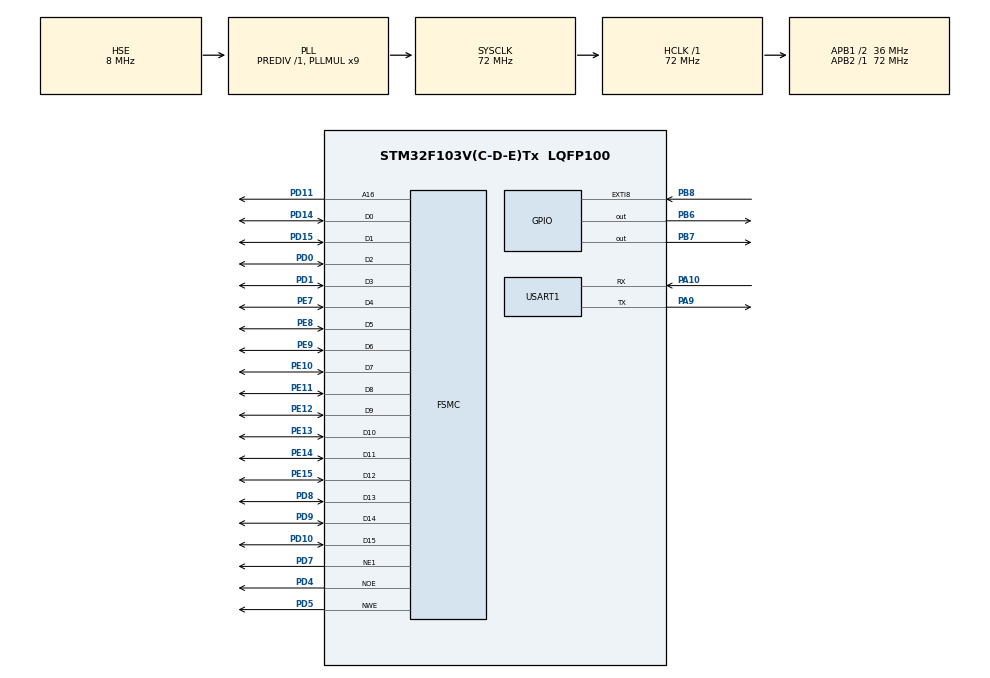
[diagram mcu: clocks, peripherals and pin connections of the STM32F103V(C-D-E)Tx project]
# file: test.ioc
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Mcu.Family=STM32F1
Mcu.Name=STM32F103V(C-D-E)Tx
Mcu.Package=LQFP100
NVIC.EXTI9_5_IRQn=true\:6\:0\:true\:false\:true\:true\:true\:true
NVIC.PriorityGroup=NVIC_PRIORITYGROUP_4
NVIC.TIM7_IRQn=true\:1\:0\:true\:false\:true\:false\:true\:true
NVIC.TimeBase=TIM7_IRQn
NVIC.TimeBaseIP=TIM7
OSC_IN.Mode=HSE-External-Oscillator
OSC_IN.Signal=RCC_OSC_IN
OSC_OUT.Mode=HSE-External-Oscillator
OSC_OUT.Signal=RCC_OSC_OUT
PA10.Mode=Asynchronous
PA10.Signal=USART1_RX
PA13.Mode=Serial_Wire
PA13.Signal=SYS_JTMS-SWDIO
PA14.Mode=Serial_Wire
PA14.Signal=SYS_JTCK-SWCLK
PA9.Mode=Asynchronous
PA9.Signal=USART1_TX
PB6.GPIO_ModeDefaultOutputPP=GPIO_MODE_OUTPUT_OD
PB6.GPIO_PuPd=GPIO_NOPULL
PB6.GPIO_Speed=GPIO_SPEED_FREQ_HIGH
PB6.PinState=GPIO_PIN_SET
PB6.Signal=GPIO_Output
PB7.GPIO_ModeDefaultOutputPP=GPIO_MODE_OUTPUT_OD
PB7.GPIO_PuPd=GPIO_NOPULL
PB7.GPIO_Speed=GPIO_SPEED_FREQ_HIGH
PB7.PinState=GPIO_PIN_SET
PB7.Signal=GPIO_Output
PB8.GPIO_ModeDefaultEXTI=GPIO_MODE_IT_FALLING
PB8.GPIO_PuPd=GPIO_PULLUP
PB8.Signal=GPXTI8
PC14-OSC32_IN.Mode=LSE-External-Oscillator
PC14-OSC32_IN.Signal=RCC_OSC32_IN
PC15-OSC32_OUT.Mode=LSE-External-Oscillator
PC15-OSC32_OUT.Signal=RCC_OSC32_OUT
PD0.Mode=16b-d1
PD0.Signal=FSMC_D2
PD1.Mode=16b-d1
PD1.Signal=FSMC_D3
PD10.Mode=16b-d1
PD10.Signal=FSMC_D15
PD11.Mode=A16_1
PD11.Signal=FSMC_A16
PD14.Mode=16b-d1
PD14.Signal=FSMC_D0
PD15.Mode=16b-d1
PD15.Signal=FSMC_D1
PD4.Mode=Lcd1
PD4.Signal=FSMC_NOE
PD5.Mode=Lcd1
PD5.Signal=FSMC_NWE
PD7.Mode=NorPsramChipSelect1_1
PD7.Signal=FSMC_NE1
PD8.Mode=16b-d1
PD8.Signal=FSMC_D13
PD9.Mode=16b-d1
PD9.Signal=FSMC_D14
PE10.Mode=16b-d1
PE10.Signal=FSMC_D7
PE11.Mode=16b-d1
PE11.Signal=FSMC_D8
PE12.Mode=16b-d1
PE12.Signal=FSMC_D9
PE13.Mode=16b-d1
PE13.Signal=FSMC_D10
PE14.Mode=16b-d1
PE14.Signal=FSMC_D11
PE15.Mode=16b-d1
PE15.Signal=FSMC_D12
PE7.Mode=16b-d1
PE7.Signal=FSMC_D4
PE8.Mode=16b-d1
PE8.Signal=FSMC_D5
PE9.Mode=16b-d1
PE9.Signal=FSMC_D6
ProjectManager.HeapSize=0x200
ProjectManager.StackSize=0x400
ProjectManager.TargetToolchain=MDK-ARM V5.32
RCC.AHBFreq_Value=72000000
RCC.APB1CLKDivider=RCC_HCLK_DIV2
RCC.APB1Freq_Value=36000000
RCC.APB1TimFreq_Value=72000000
RCC.APB2Freq_Value=72000000
RCC.APB2TimFreq_Value=72000000
RCC.HCLKFreq_Value=72000000
RCC.PLLMUL=RCC_PLL_MUL9
RCC.PLLSourceVirtual=RCC_PLLSOURCE_HSE
RCC.SYSCLKFreq_VALUE=72000000
RCC.SYSCLKSource=RCC_SYSCLKSOURCE_PLLCLK
RCC.USBFreq_Value=72000000
TIM6.AutoReloadPreload=TIM_AUTORELOAD_PRELOAD_ENABLE
TIM6.Prescaler=71
USART1.VirtualMode=VM_ASYNC
VP_SYS_VS_tim7.Mode=TIM7
VP_TIM6_VS_ClockSourceINT.Mode=Enable_Timer
board=custom

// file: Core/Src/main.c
/* USER CODE BEGIN Header */
/*
 * @Author: userName userEmail
 * @Date: 2026-02-24 22:10:03
 * @LastEditTime: 2026-02-26 10:42:33
 * @FilePath: \test_EIDEd:\MCU\stm32\stm32_practise\VS+HAL\stm32_HAL-FreeRTOS-LVGL-\test\Core\Src\main.c
 * @Description: 此项目用于FreeRTOS+LVGL,基于stm32F103VET6实现.
 * 外设LCD使用ILI9341作为驱动芯片,使用FSMC进行16位并行传输
 */
/**
  ******************************************************************************
  * @file           : main.c
  * @brief          : Main program body
  ******************************************************************************
  * @attention
  *
  * Copyright (c) 2026 STMicroelectronics.
  * All rights reserved.
  *
  * This software is licensed under terms that can be found in the LICENSE file
  * in the root directory of this software component.
  * If no LICENSE file comes with this software, it is provided AS-IS.
  *
  ******************************************************************************
  */
/* USER CODE END Header */
#include "main.h"
#include "tim.h"
#include "usart.h"
#include "gpio.h"
#include "fsmc.h"

/* USER CODE BEGIN Includes */
#include "LVGL_demo.h"
#include "Touch_XPT2046.h"
/* USER CODE END Includes */

void SystemClock_Config(void);

/* USER CODE BEGIN 0 */
void Delay_us(uint16_t us)
{
    if (us == 0) return;
    TIM6->CNT = 0;                          // 清零计数器
    while (TIM6->CNT < us);                 // 等待 CNT 达到 us
}
/* USER CODE END 0 */

int main(void)
{

  /* MCU Configuration--------------------------------------------------------*/

  /* Reset of all peripherals, Initializes the Flash interface and the Systick. */
  HAL_Init();

  /* Configure the system clock */
  SystemClock_Config();

  /* Initialize all configured peripherals */
  MX_GPIO_Init();
  MX_USART1_UART_Init();
  MX_FSMC_Init();
  MX_TIM6_Init();
  /* USER CODE BEGIN 2 */

  HAL_TIM_Base_Start(&htim6);
  HAL_Delay(500);
  FreeRTOS_Start();

  /* USER CODE END 2 */

  /* Infinite loop */
  while (1)
  {

  }
}

void SystemClock_Config(void)
{
  RCC_OscInitTypeDef RCC_OscInitStruct = {0};
  RCC_ClkInitTypeDef RCC_ClkInitStruct = {0};

  /** Initializes the RCC Oscillators according to the specified parameters
  * in the RCC_OscInitTypeDef structure.
  */
  RCC_OscInitStruct.OscillatorType = RCC_OSCILLATORTYPE_HSE;
  RCC_OscInitStruct.HSEState = RCC_HSE_ON;
  RCC_OscInitStruct.HSEPredivValue = RCC_HSE_PREDIV_DIV1;
  RCC_OscInitStruct.HSIState = RCC_HSI_ON;
  RCC_OscInitStruct.PLL.PLLState = RCC_PLL_ON;
  RCC_OscInitStruct.PLL.PLLSource = RCC_PLLSOURCE_HSE;
  RCC_OscInitStruct.PLL.PLLMUL = RCC_PLL_MUL9;
  if (HAL_RCC_OscConfig(&RCC_OscInitStruct) != HAL_OK)
  {
    Error_Handler();
  }

  /** Initializes the CPU, AHB and APB buses clocks
  */
  RCC_ClkInitStruct.ClockType = RCC_CLOCKTYPE_HCLK|RCC_CLOCKTYPE_SYSCLK
                              |RCC_CLOCKTYPE_PCLK1|RCC_CLOCKTYPE_PCLK2;
  RCC_ClkInitStruct.SYSCLKSource = RCC_SYSCLKSOURCE_PLLCLK;
  RCC_ClkInitStruct.AHBCLKDivider = RCC_SYSCLK_DIV1;
  RCC_ClkInitStruct.APB1CLKDivider = RCC_HCLK_DIV2;
  RCC_ClkInitStruct.APB2CLKDivider = RCC_HCLK_DIV1;

  if (HAL_RCC_ClockConfig(&RCC_ClkInitStruct, FLASH_LATENCY_2) != HAL_OK)
  {
    Error_Handler();
  }
}

void HAL_TIM_PeriodElapsedCallback(TIM_HandleTypeDef *htim)
{
  if (htim->Instance == TIM7)
  {
    HAL_IncTick();
  }
}

void Error_Handler(void)
{
  /* USER CODE BEGIN Error_Handler_Debug */
  /* User can add his own implementation to report the HAL error return state */
  __disable_irq();
  while (1)
  {
    /**************PB6LED闪烁代表进入error*****************/
    // HAL_GPIO_TogglePin(GPIOB,GPIO_PIN_6);
    // HAL_Delay(500);
  }
  /* USER CODE END Error_Handler_Debug */
}
